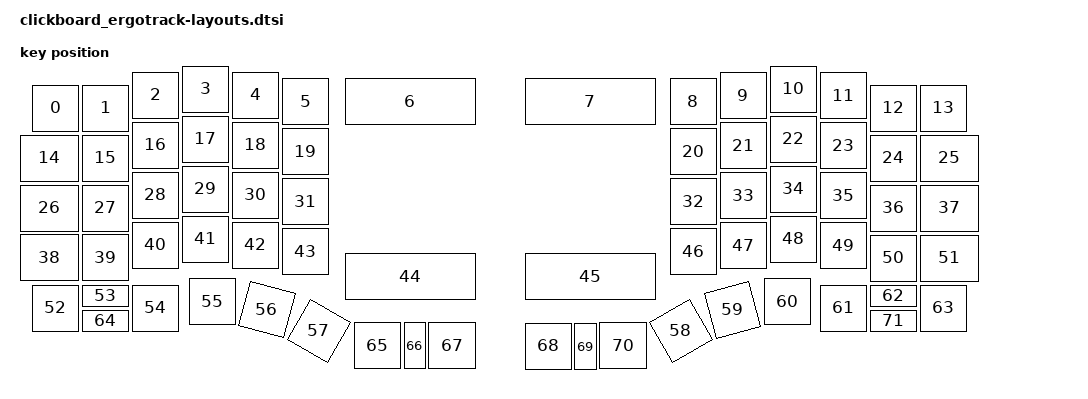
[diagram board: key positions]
#include <physical_layouts.dtsi>

/ {
    physical_layout0: physical_layout_0 {
        compatible = "zmk,physical-layout";
        display-name = "ClickBoard ErgoTrack";
        transform = <&default_transform>;
        kscan = <&kscan0>;
        keys
            = <&key_physical_attrs 100 100 25 38 0 0 0>
            , <&key_physical_attrs 100 100 125 38 0 0 0>
            , <&key_physical_attrs 100 100 225 12 0 0 0>
            , <&key_physical_attrs 100 100 325 0 0 0 0>
            , <&key_physical_attrs 100 100 425 12 0 0 0>
            , <&key_physical_attrs 100 100 525 25 0 0 0>
            , <&key_physical_attrs 268 100 650 25 0 0 0>
            , <&key_physical_attrs 268 100 1010 25 0 0 0>
            , <&key_physical_attrs 100 100 1300 25 0 0 0>
            , <&key_physical_attrs 100 100 1400 13 0 0 0>
            , <&key_physical_attrs 100 100 1500 0 0 0 0>
            , <&key_physical_attrs 100 100 1600 13 0 0 0>
            , <&key_physical_attrs 100 100 1700 38 0 0 0>
            , <&key_physical_attrs 100 100 1800 38 0 0 0>
            , <&key_physical_attrs 125 100 0 138 0 0 0>
            , <&key_physical_attrs 100 100 125 138 0 0 0>
            , <&key_physical_attrs 100 100 225 112 0 0 0>
            , <&key_physical_attrs 100 100 325 100 0 0 0>
            , <&key_physical_attrs 100 100 425 112 0 0 0>
            , <&key_physical_attrs 100 100 525 125 0 0 0>
            , <&key_physical_attrs 100 100 1300 125 0 0 0>
            , <&key_physical_attrs 100 100 1400 113 0 0 0>
            , <&key_physical_attrs 100 100 1500 100 0 0 0>
            , <&key_physical_attrs 100 100 1600 113 0 0 0>
            , <&key_physical_attrs 100 100 1700 138 0 0 0>
            , <&key_physical_attrs 125 100 1800 138 0 0 0>
            , <&key_physical_attrs 125 100 0 238 0 0 0>
            , <&key_physical_attrs 100 100 125 238 0 0 0>
            , <&key_physical_attrs 100 100 225 212 0 0 0>
            , <&key_physical_attrs 100 100 325 200 0 0 0>
            , <&key_physical_attrs 100 100 425 212 0 0 0>
            , <&key_physical_attrs 100 100 525 225 0 0 0>
            , <&key_physical_attrs 100 100 1300 225 0 0 0>
            , <&key_physical_attrs 100 100 1400 213 0 0 0>
            , <&key_physical_attrs 100 100 1500 200 0 0 0>
            , <&key_physical_attrs 100 100 1600 213 0 0 0>
            , <&key_physical_attrs 100 100 1700 238 0 0 0>
            , <&key_physical_attrs 125 100 1800 238 0 0 0>
            , <&key_physical_attrs 125 100 0 337 0 0 0>
            , <&key_physical_attrs 100 100 125 337 0 0 0>
            , <&key_physical_attrs 100 100 225 312 0 0 0>
            , <&key_physical_attrs 100 100 325 300 0 0 0>
            , <&key_physical_attrs 100 100 425 312 0 0 0>
            , <&key_physical_attrs 100 100 525 325 0 0 0>
            , <&key_physical_attrs 268 100 650 375 0 0 0>
            , <&key_physical_attrs 268 100 1010 375 0 0 0>
            , <&key_physical_attrs 100 100 1300 325 0 0 0>
            , <&key_physical_attrs 100 100 1400 313 0 0 0>
            , <&key_physical_attrs 100 100 1500 300 0 0 0>
            , <&key_physical_attrs 100 100 1600 313 0 0 0>
            , <&key_physical_attrs 100 100 1700 338 0 0 0>
            , <&key_physical_attrs 125 100 1800 338 0 0 0>
            , <&key_physical_attrs 100 100 25 438 0 0 0>
            , <&key_physical_attrs 100 50 125 438 0 0 0>
            , <&key_physical_attrs 100 100 225 438 0 0 0>
            , <&key_physical_attrs 100 100 338 425 0 0 0>
            , <&key_physical_attrs 100 100 558 295 1500 0 0>
            , <&key_physical_attrs 100 100 738 112 3000 0 0>
            , <&key_physical_attrs 100 100 831 1075 (-3000) 0 0>
            , <&key_physical_attrs 100 100 1203 795 (-1500) 0 0>
            , <&key_physical_attrs 100 100 1488 425 0 0 0>
            , <&key_physical_attrs 100 100 1600 438 0 0 0>
            , <&key_physical_attrs 100 50 1700 438 0 0 0>
            , <&key_physical_attrs 100 100 1800 438 0 0 0>
            , <&key_physical_attrs 100 50 125 488 0 0 0>
            , <&key_physical_attrs 100 100 668 513 0 0 0>
            , <&key_physical_attrs 50 100 768 513 0 0 0>
            , <&key_physical_attrs 100 100 818 513 0 0 0>
            , <&key_physical_attrs 100 100 1010 514 0 0 0>
            , <&key_physical_attrs 50 100 1110 514 0 0 0>
            , <&key_physical_attrs 100 100 1160 513 0 0 0>
            , <&key_physical_attrs 100 50 1700 488 0 0 0>
            ;
    };
};
